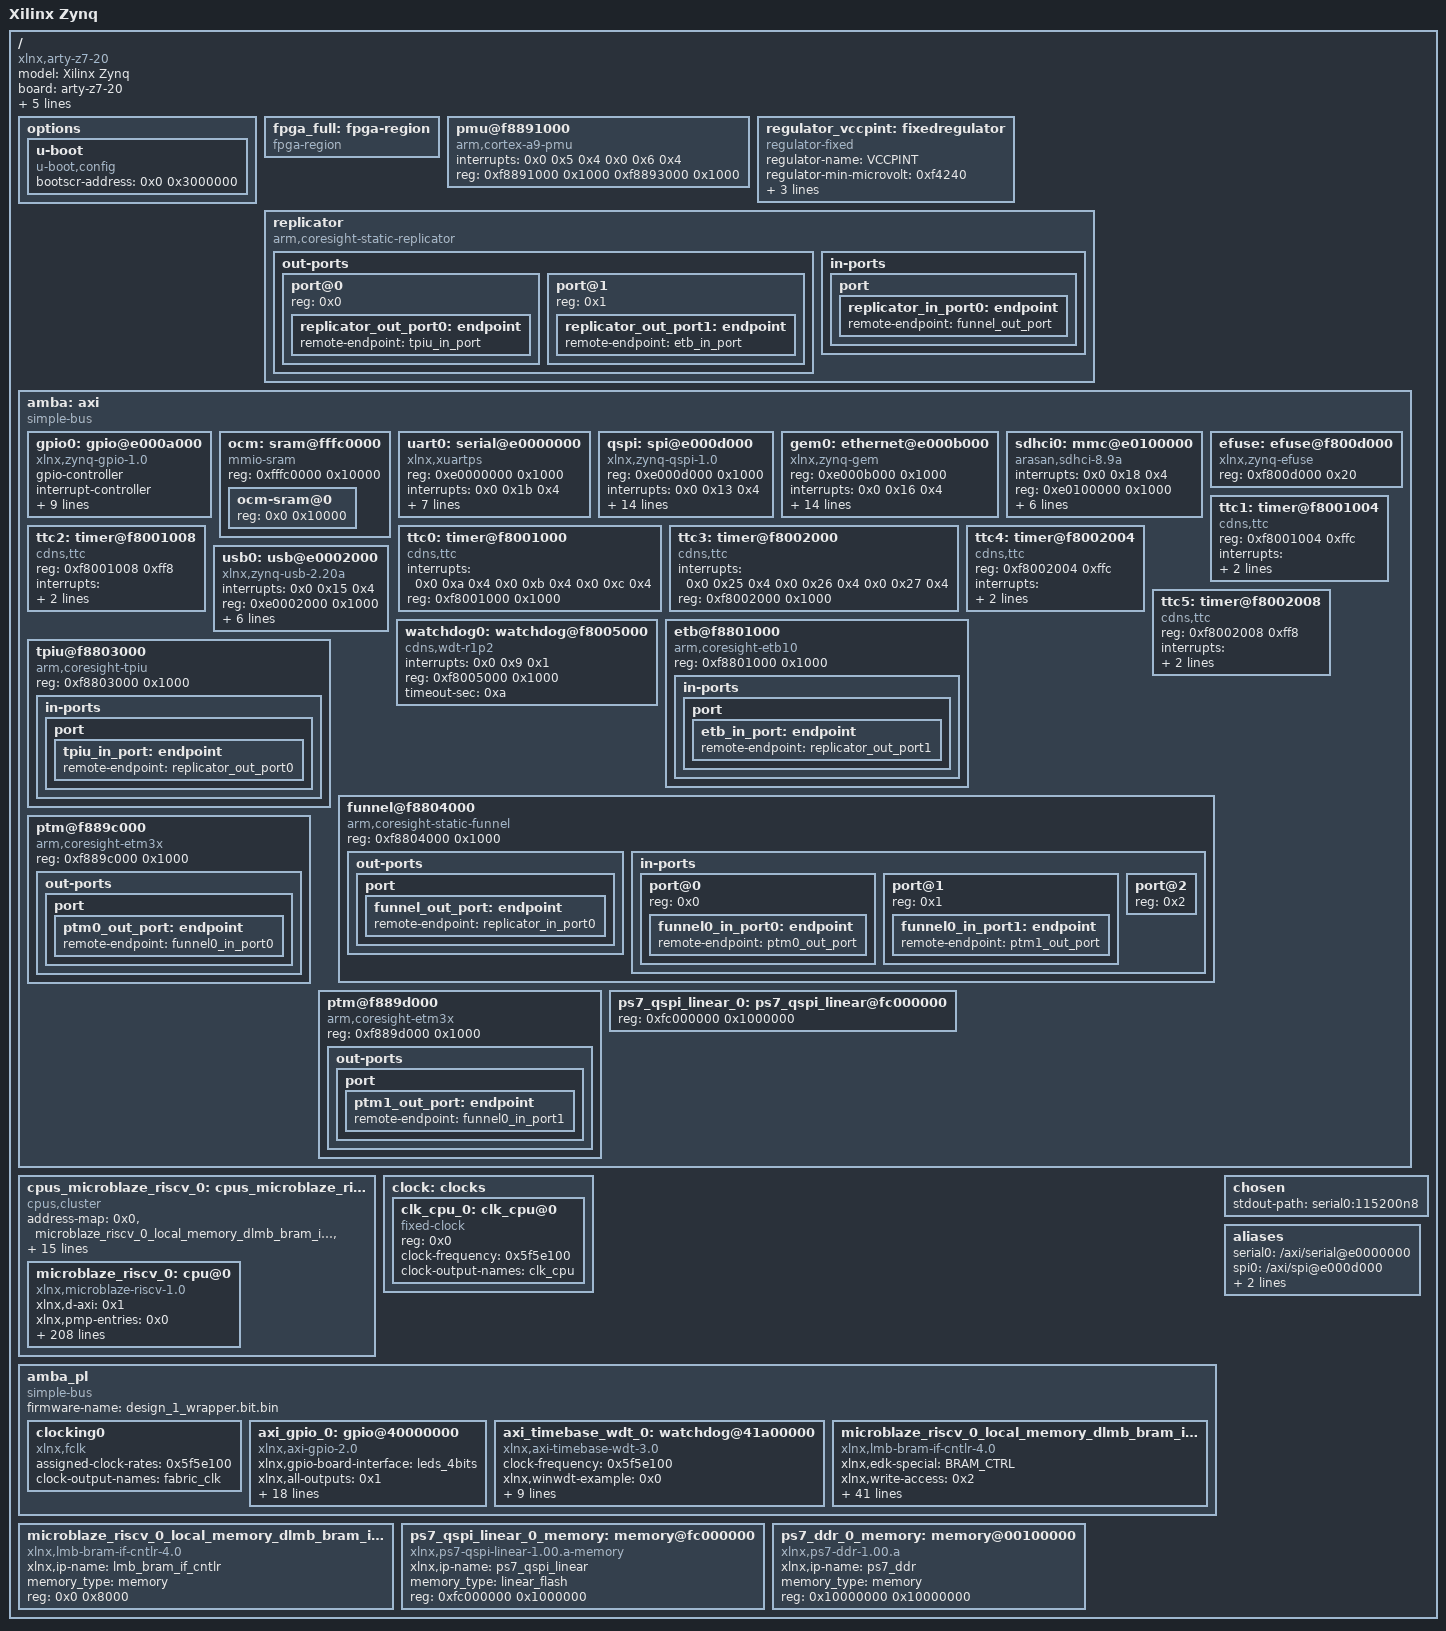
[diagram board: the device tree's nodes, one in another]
/dts-v1/;
/ {
        #address-cells = <0x1>;
        #size-cells = <0x1>;
        compatible = "xlnx,arty-z7-20";
        model = "Xilinx Zynq";
        board = "arty-z7-20";
        device_id = "7z020";
        slrcount = <0x1>;
        family = "Zynq";
        speed_grade = "1";
        pruned-sdt = <0x1>;

        options {

                u-boot {
                        compatible = "u-boot,config";
                        bootscr-address = <0x0 0x3000000>;
                };
        };

        fpga_full: fpga-region {
                phandle = <0x35>;
                compatible = "fpga-region";
                #address-cells = <0x1>;
                #size-cells = <0x1>;
                ranges;
        };

        pmu@f8891000 {
                compatible = "arm,cortex-a9-pmu";
                interrupts = <0x0 0x5 0x4 0x0 0x6 0x4>;
                reg = <0xf8891000 0x1000 0xf8893000 0x1000>;
        };

        regulator_vccpint: fixedregulator {
                phandle = <0x22>;
                compatible = "regulator-fixed";
                regulator-name = "VCCPINT";
                regulator-min-microvolt = <0xf4240>;
                regulator-max-microvolt = <0xf4240>;
                regulator-boot-on;
                regulator-always-on;
        };

        replicator {
                compatible = "arm,coresight-static-replicator";
                clock-names = "apb_pclk", "dbg_trc", "dbg_apb";

                out-ports {
                        #address-cells = <0x1>;
                        #size-cells = <0x0>;

                        port@0 {
                                reg = <0x0>;

                                replicator_out_port0: endpoint {
                                        phandle = <0x27>;
                                        remote-endpoint = <&tpiu_in_port>;
                                };
                        };

                        port@1 {
                                reg = <0x1>;

                                replicator_out_port1: endpoint {
                                        phandle = <0x26>;
                                        remote-endpoint = <&etb_in_port>;
                                };
                        };
                };

                in-ports {

                        port {

                                replicator_in_port0: endpoint {
                                        phandle = <0x28>;
                                        remote-endpoint = <&funnel_out_port>;
                                };
                        };
                };
        };

        amba: axi {
                phandle = <0x1>;
                bootph-all;
                compatible = "simple-bus";
                #address-cells = <0x1>;
                #size-cells = <0x1>;
                ranges;

                gpio0: gpio@e000a000 {
                        phandle = <0x7>;
                        compatible = "xlnx,zynq-gpio-1.0";
                        #gpio-cells = <0x2>;
                        gpio-controller;
                        interrupt-controller;
                        #interrupt-cells = <0x2>;
                        interrupts = <0x0 0x14 0x4>;
                        reg = <0xe000a000 0x1000>;
                        xlnx,mio-gpio-mask = <0x5600>;
                        status = "okay";
                        gpio-mask-high = <0x0>;
                        xlnx,emio-gpio-width = <0x40>;
                        xlnx,ip-name = "ps7_gpio";
                        gpio-mask-low = <0x5600>;
                        emio-gpio-width = <0x40>;
                        xlnx,name = "ps7_gpio_0";
                };

                ocm: sram@fffc0000 {
                        phandle = <0x3a>;
                        compatible = "mmio-sram";
                        reg = <0xfffc0000 0x10000>;
                        #address-cells = <0x1>;
                        #size-cells = <0x1>;
                        ranges = <0x0 0xfffc0000 0x10000>;

                        ocm-sram@0 {
                                reg = <0x0 0x10000>;
                        };
                };

                uart0: serial@e0000000 {
                        phandle = <0x5>;
                        compatible = "xlnx,xuartps", "cdns,uart-r1p8";
                        status = "okay";
                        clock-names = "uart_clk", "pclk";
                        reg = <0xe0000000 0x1000>;
                        interrupts = <0x0 0x1b 0x4>;
                        xlnx,clock-freq = <0x5f5e100>;
                        xlnx,has-modem = <0x0>;
                        xlnx,ip-name = "ps7_uart";
                        cts-override;
                        port-number = <0x0>;
                        xlnx,uart-clk-freq-hz = <0x5f5e100>;
                        xlnx,name = "ps7_uart_0";
                };

                qspi: spi@e000d000 {
                        phandle = <0xa>;
                        compatible = "xlnx,zynq-qspi-1.0";
                        reg = <0xe000d000 0x1000>;
                        interrupts = <0x0 0x13 0x4>;
                        clock-names = "ref_clk", "pclk";
                        status = "okay";
                        #address-cells = <0x1>;
                        #size-cells = <0x0>;
                        xlnx,qspi-fbclk = <0x0>;
                        num-cs = <0x1>;
                        xlnx,qspi-clk-freq-hz = <0xbebc200>;
                        xlnx,bus-width = <0x2>;
                        xlnx,ip-name = "ps7_qspi";
                        spi-rx-bus-width = <0x4>;
                        xlnx,connection-mode = <0x0>;
                        spi-tx-bus-width = <0x4>;
                        xlnx,clock-freq = <0xbebc200>;
                        xlnx,fb-clk = <0x1>;
                        xlnx,qspi-mode = <0x0>;
                        xlnx,name = "ps7_qspi_0";
                        xlnx,qspi-bus-width = <0x2>;
                        is-dual = <0x0>;
                };

                gem0: ethernet@e000b000 {
                        phandle = <0x8>;
                        compatible = "xlnx,zynq-gem", "cdns,gem";
                        reg = <0xe000b000 0x1000>;
                        status = "okay";
                        interrupts = <0x0 0x16 0x4>;
                        clock-names = "pclk", "hclk", "tx_clk";
                        #address-cells = <0x1>;
                        #size-cells = <0x0>;
                        xlnx,has-mdio = <0x1>;
                        phy-mode = "rgmii-id";
                        xlnx,enet-slcr-1000mbps-div0 = <0x8>;
                        xlnx,enet-slcr-10mbps-div0 = <0x8>;
                        enet-reset = <0x7 0x9 0x0>;
                        xlnx,enet-slcr-1000mbps-div1 = <0x1>;
                        xlnx,enet-slcr-10mbps-div1 = <0x32>;
                        xlnx,ip-name = "ps7_ethernet";
                        xlnx,eth-mode = <0x1>;
                        xlnx,enet-reset = "MIO , 9";
                        xlnx,enet-clk-freq-hz = <0x7735940>;
                        xlnx,enet-slcr-100mbps-div0 = <0x8>;
                        xlnx,enet-slcr-100mbps-div1 = <0x5>;
                        xlnx,name = "ps7_ethernet_0";
                };

                sdhci0: mmc@e0100000 {
                        phandle = <0x9>;
                        compatible = "arasan,sdhci-8.9a";
                        status = "okay";
                        clock-names = "clk_xin", "clk_ahb";
                        interrupts = <0x0 0x18 0x4>;
                        reg = <0xe0100000 0x1000>;
                        xlnx,has-power = <0x0>;
                        xlnx,ip-name = "ps7_sdio";
                        xlnx,sdio-clk-freq-hz = <0x2faf080>;
                        xlnx,has-wp = <0x0>;
                        xlnx,has-cd = <0x1>;
                        xlnx,name = "ps7_sd_0";
                };

                efuse: efuse@f800d000 {
                        phandle = <0x45>;
                        compatible = "xlnx,zynq-efuse";
                        reg = <0xf800d000 0x20>;
                };

                ttc0: timer@f8001000 {
                        phandle = <0x46>;
                        interrupts = <0x0 0xa 0x4 0x0 0xb 0x4 0x0 0xc 0x4>;
                        compatible = "cdns,ttc";
                        reg = <0xf8001000 0x1000>;
                };

                ttc1: timer@f8001004 {
                        phandle = <0x54>;
                        reg = <0xf8001004 0xffc>;
                        compatible = "cdns,ttc";
                        interrupts = <0x0 0xa 0x4 0x0 0xb 0x4 0x0 0xc 0x4>;
                        lop-dynamic-ttc-node = <0x1>;
                };

                ttc2: timer@f8001008 {
                        phandle = <0x55>;
                        reg = <0xf8001008 0xff8>;
                        compatible = "cdns,ttc";
                        interrupts = <0x0 0xa 0x4 0x0 0xb 0x4 0x0 0xc 0x4>;
                        lop-dynamic-ttc-node = <0x1>;
                };

                ttc3: timer@f8002000 {
                        phandle = <0x47>;
                        interrupts = <0x0 0x25 0x4 0x0 0x26 0x4 0x0 0x27 0x4>;
                        compatible = "cdns,ttc";
                        reg = <0xf8002000 0x1000>;
                };

                ttc4: timer@f8002004 {
                        phandle = <0x56>;
                        reg = <0xf8002004 0xffc>;
                        compatible = "cdns,ttc";
                        interrupts = <0x0 0x25 0x4 0x0 0x26 0x4 0x0 0x27 0x4>;
                        lop-dynamic-ttc-node = <0x1>;
                };

                ttc5: timer@f8002008 {
                        phandle = <0x57>;
                        reg = <0xf8002008 0xff8>;
                        compatible = "cdns,ttc";
                        interrupts = <0x0 0x25 0x4 0x0 0x26 0x4 0x0 0x27 0x4>;
                        lop-dynamic-ttc-node = <0x1>;
                };

                usb0: usb@e0002000 {
                        phandle = <0x6>;
                        compatible = "xlnx,zynq-usb-2.20a", "chipidea,usb2";
                        status = "okay";
                        interrupts = <0x0 0x15 0x4>;
                        reg = <0xe0002000 0x1000>;
                        phy_type = "ulpi";
                        xlnx,usb-reset = "MIO , 46";
                        xlnx,ip-name = "ps7_usb";
                        xlnx,enable-superspeed = <0x0>;
                        usb-reset = <0x7 0x2e 0x0>;
                        xlnx,name = "ps7_usb_0";
                };

                watchdog0: watchdog@f8005000 {
                        phandle = <0x49>;
                        compatible = "cdns,wdt-r1p2";
                        interrupts = <0x0 0x9 0x1>;
                        reg = <0xf8005000 0x1000>;
                        timeout-sec = <0xa>;
                };

                etb@f8801000 {
                        compatible = "arm,coresight-etb10", "arm,primecell";
                        reg = <0xf8801000 0x1000>;
                        clock-names = "apb_pclk", "dbg_trc", "dbg_apb";

                        in-ports {

                                port {

                                        etb_in_port: endpoint {
                                                phandle = <0x24>;
                                                remote-endpoint = <&replicator_out_port1>;
                                        };
                                };
                        };
                };

                tpiu@f8803000 {
                        compatible = "arm,coresight-tpiu", "arm,primecell";
                        reg = <0xf8803000 0x1000>;
                        clock-names = "apb_pclk", "dbg_trc", "dbg_apb";

                        in-ports {

                                port {

                                        tpiu_in_port: endpoint {
                                                phandle = <0x23>;
                                                remote-endpoint = <&replicator_out_port0>;
                                        };
                                };
                        };
                };

                funnel@f8804000 {
                        compatible = "arm,coresight-static-funnel", "arm,primecell";
                        reg = <0xf8804000 0x1000>;
                        clock-names = "apb_pclk", "dbg_trc", "dbg_apb";

                        out-ports {

                                port {

                                        funnel_out_port: endpoint {
                                                phandle = <0x25>;
                                                remote-endpoint = <&replicator_in_port0>;
                                        };
                                };
                        };

                        in-ports {
                                #address-cells = <0x1>;
                                #size-cells = <0x0>;

                                port@0 {
                                        reg = <0x0>;

                                        funnel0_in_port0: endpoint {
                                                phandle = <0x2c>;
                                                remote-endpoint = <&ptm0_out_port>;
                                        };
                                };

                                port@1 {
                                        reg = <0x1>;

                                        funnel0_in_port1: endpoint {
                                                phandle = <0x2e>;
                                                remote-endpoint = <&ptm1_out_port>;
                                        };
                                };

                                port@2 {
                                        reg = <0x2>;
                                };
                        };
                };

                ptm@f889c000 {
                        compatible = "arm,coresight-etm3x", "arm,primecell";
                        reg = <0xf889c000 0x1000>;
                        clock-names = "apb_pclk", "dbg_trc", "dbg_apb";

                        out-ports {

                                port {

                                        ptm0_out_port: endpoint {
                                                phandle = <0x29>;
                                                remote-endpoint = <&funnel0_in_port0>;
                                        };
                                };
                        };
                };

                ptm@f889d000 {
                        compatible = "arm,coresight-etm3x", "arm,primecell";
                        reg = <0xf889d000 0x1000>;
                        clock-names = "apb_pclk", "dbg_trc", "dbg_apb";

                        out-ports {

                                port {

                                        ptm1_out_port: endpoint {
                                                phandle = <0x2a>;
                                                remote-endpoint = <&funnel0_in_port1>;
                                        };
                                };
                        };
                };

                ps7_qspi_linear_0: ps7_qspi_linear@fc000000 {
                        phandle = <0x4e>;
                        reg = <0xfc000000 0x1000000>;
                };
        };

        cpus_microblaze_riscv_0: cpus_microblaze_riscv@0 {
                phandle = <0x4f>;
                #cpu-mask-cells = <0x1>;
                compatible = "cpus,cluster";
                #address-cells = <0x1>;
                #size-cells = <0x0>;
                address-map = <0x0 &microblaze_riscv_0_local_memory_dlmb_bram_if_cntlr_memory 0x0 0x8000>,
                 <0x0 &microblaze_riscv_0_local_memory_dlmb_bram_if_cntlr 0x0 0x8000>,
                 <0x10000000 &ps7_ddr_0_memory 0x10000000 0x10000000>,
                 <0x40000000 &axi_gpio_0 0x40000000 0x10000>,
                 <0x41a00000 &axi_timebase_wdt_0 0x41a00000 0x10000>,
                 <0xe0000000 &uart0 0xe0000000 0x1000>,
                 <0xe0002000 &usb0 0xe0002000 0x1000>,
                 <0xe000a000 &gpio0 0xe000a000 0x1000>,
                 <0xe000b000 &gem0 0xe000b000 0x1000>,
                 <0xe0100000 &sdhci0 0xe0100000 0x1000>,
                 <0xe000d000 &qspi 0xe000d000 0x1000>,
                 <0xfc000000 &ps7_qspi_linear_0_memory 0xfc000000 0x1000000>;
                #ranges-address-cells = <0x1>;
                #ranges-size-cells = <0x1>;

                microblaze_riscv_0: cpu@0 {
                        phandle = <0x50>;
                        xlnx,d-axi = <0x1>;
                        xlnx,pmp-entries = <0x0>;
                        xlnx,temporal-depth = <0x0>;
                        xlnx,dcache-force-tag-lutram = <0x0>;
                        reg = <0x0>;
                        xlnx,interrupt-is-edge = <0x0>;
                        xlnx,use-mmu = <0x0>;
                        xlnx,dc-axi-mon = <0x0>;
                        xlnx,debug-trace-async-reset = <0x0>;
                        xlnx,part = "xc7z020clg400-1";
                        xlnx,use-config-reset = <0x0>;
                        xlnx,family = "zynq";
                        xlnx,use-sleep = <0x0>;
                        xlnx,enable-discrete-ports = <0x0>;
                        xlnx,d-lmb = <0x1>;
                        xlnx,debug-interface = <0x0>;
                        xlnx,use-ext-brk = <0x0>;
                        xlnx,debug-enabled = <0x1>;
                        xlnx,daddr-size = <0x20>;
                        xlnx,use-extended-fsl-instr = <0x0>;
                        xlnx,branch-target-cache-size = <0x0>;
                        bus-handle = <0x33>;
                        xlnx,pmp-addr0 = <0x0>;
                        xlnx,pmp-addr1 = <0x0>;
                        xlnx,pmp-addr2 = <0x0>;
                        xlnx,pmp-addr3 = <0x0>;
                        xlnx,pmp-addr4 = <0x0>;
                        xlnx,edk-special = "microblaze_riscv";
                        xlnx,use-dcache = <0x0>;
                        xlnx,pmp-addr5 = <0x0>;
                        xlnx,use-muldiv = <0x0>;
                        xlnx,pmp-addr6 = <0x0>;
                        xlnx,use-axi-dp-ext-addr = <0x0>;
                        xlnx,pmp-addr7 = <0x0>;
                        xlnx,pmp-addr8 = <0x0>;
                        xlnx,pmp-addr9 = <0x0>;
                        xlnx,i-axi = <0x0>;
                        xlnx,icache-streams = <0x0>;
                        xlnx,i-lmb-has-prot = <0x0>;
                        xlnx,num-sync-ff-dbg-clk = <0x1>;
                        xlnx,icache-byte-size = <0x2000>;
                        xlnx,pmp-addr10 = <0x0>;
                        d-cache-size = <0x2000>;
                        xlnx,pmp-addr11 = <0x0>;
                        xlnx,pmp-addr12 = <0x0>;
                        xlnx,pmp-addr13 = <0x0>;
                        xlnx,pmp-addr14 = <0x0>;
                        xlnx,pmp-addr15 = <0x0>;
                        xlnx,avoid-primitives = <0x0>;
                        xlnx,pmp-addr16 = <0x0>;
                        xlnx,pmp-addr17 = <0x0>;
                        xlnx,pmp-addr18 = <0x0>;
                        xlnx,pdaddr-size = <0x20>;
                        xlnx,pmp-addr19 = <0x0>;
                        xlnx,pmp-addr20 = <0x0>;
                        xlnx,pmp-addr21 = <0x0>;
                        xlnx,i-lmb = <0x1>;
                        xlnx,pmp-addr22 = <0x0>;
                        xlnx,lmb-data-size = <0x20>;
                        xlnx,lockstep-select = <0x0>;
                        xlnx,pmp-addr23 = <0x0>;
                        timebase-frequency = <0x5f5e100>;
                        xlnx,pmp-addr24 = <0x0>;
                        xlnx,dcache-data-width = <0x0>;
                        xlnx,icache-force-tag-lutram = <0x0>;
                        xlnx,pmp-addr25 = <0x0>;
                        xlnx,pmp-addr26 = <0x0>;
                        xlnx,use-branch-target-cache = <0x0>;
                        xlnx,pmp-addr27 = <0x0>;
                        xlnx,number-of-pc-brk = <0x1>;
                        xlnx,pmp-addr28 = <0x0>;
                        xlnx,imprecise-exceptions = <0x0>;
                        xlnx,pmp-addr29 = <0x0>;
                        xlnx,pmp-addr30 = <0x0>;
                        xlnx,pmp-addr31 = <0x0>;
                        xlnx,pmp-addr32 = <0x0>;
                        model = "microblaze_riscv,1.0";
                        xlnx,pmp-addr33 = <0x0>;
                        xlnx,pmp-addr34 = <0x0>;
                        xlnx,pmp-addr35 = <0x0>;
                        xlnx,pmp-addr36 = <0x0>;
                        d-cache-highaddr = <0x3fffffff>;
                        xlnx,optimization = <0x0>;
                        xlnx,pmp-addr37 = <0x0>;
                        xlnx,pmp-addr38 = <0x0>;
                        xlnx,pmp-addr39 = <0x0>;
                        xlnx,pmp-addr40 = <0x0>;
                        xlnx,pmp-addr41 = <0x0>;
                        xlnx,d-lmb-mon = <0x0>;
                        xlnx,pmp-addr42 = <0x0>;
                        xlnx,pmp-addr43 = <0x0>;
                        xlnx,pmp-addr44 = <0x0>;
                        xlnx,pmp-addr45 = <0x0>;
                        xlnx,pmp-addr46 = <0x0>;
                        xlnx,pmp-addr47 = <0x0>;
                        xlnx,pmp-addr48 = <0x0>;
                        xlnx,fault-tolerant = <0x0>;
                        xlnx,pmp-addr49 = <0x0>;
                        xlnx,pmp-addr50 = <0x0>;
                        xlnx,pmp-addr51 = <0x0>;
                        xlnx,pmp-enhancements = <0x0>;
                        d-cache-line-size = <0x10>;
                        xlnx,mmu-privileged-instr = <0x0>;
                        xlnx,pmp-addr52 = <0x0>;
                        clock-frequency = <0x5f5e100>;
                        xlnx,pmp-addr53 = <0x0>;
                        xlnx,pmp-addr54 = <0x0>;
                        xlnx,pmp-addr55 = <0x0>;
                        xlnx,i-lmb-protocol = <0x0>;
                        xlnx,pmp-addr56 = <0x0>;
                        xlnx,pmp-addr57 = <0x0>;
                        xlnx,dp-axi-mon = <0x0>;
                        xlnx,pmp-addr58 = <0x0>;
                        xlnx,pmp-addr59 = <0x0>;
                        xlnx,pmp-addr60 = <0x0>;
                        xlnx,pmp-addr61 = <0x0>;
                        xlnx,pmp-addr62 = <0x0>;
                        xlnx,pmp-addr63 = <0x0>;
                        xlnx,debug-external-trace = <0x0>;
                        xlnx,addr-size = <0x20>;
                        xlnx,debug-num-progbuf = <0x2>;
                        xlnx,debug-event-counters = <0x0>;
                        xlnx,edk-iptype = "PROCESSOR";
                        xlnx,debug-latency-counters = <0x0>;
                        xlnx,interconnect = <0x2>;
                        xlnx,edge-is-positive = <0x1>;
                        xlnx,use-icache = <0x0>;
                        xlnx,async-wakeup = <0x3>;
                        xlnx,s-axi = <0x0>;
                        xlnx,use-ext-nm-brk = <0x0>;
                        xlnx,ic-axi-mon = <0x0>;
                        xlnx,archid = <0x1>;
                        xlnx,num-sync-ff-clk-irq = <0x1>;
                        xlnx,freq = <0x5f5e100>;
                        xlnx,lockstep-master = <0x0>;
                        xlnx,pmp-cfg0 = <0x0>;
                        xlnx,pmp-cfg1 = <0x0>;
                        xlnx,iaddr-size = <0x20>;
                        xlnx,interrupt-mon = <0x0>;
                        xlnx,pmp-cfg2 = <0x0>;
                        xlnx,number-of-wr-addr-brk = <0x0>;
                        xlnx,pmp-cfg3 = <0x0>;
                        xlnx,pmp-cfg4 = <0x0>;
                        xlnx,use-interrupt = <0x0>;
                        xlnx,pmp-cfg5 = <0x0>;
                        xlnx,async-interrupt = <0x1>;
                        xlnx,pc-width = <0xf>;
                        xlnx,pmp-cfg6 = <0x0>;
                        xlnx,icache-victims = <0x0>;
                        xlnx,pmp-cfg7 = <0x0>;
                        xlnx,pmp-cfg8 = <0x0>;
                        xlnx,pmp-cfg9 = <0x0>;
                        xlnx,use-bitman-a = <0x0>;
                        xlnx,use-bitman-b = <0x0>;
                        xlnx,use-bitman-c = <0x0>;
                        xlnx,i-lmb-mon = <0x0>;
                        xlnx,dcache-byte-size = <0x2000>;
                        xlnx,data-size = <0x20>;
                        compatible = "xlnx,microblaze-riscv-1.0", "xlnx,microblaze_riscv";
                        xlnx,pmp-debug-inhibit = <0x0>;
                        xlnx,use-sstc = <0x1>;
                        xlnx,fsl-exception = <0x0>;
                        xlnx,dcache-use-writeback = <0x0>;
                        device_type = "cpu";
                        xlnx,impid = <0x1>;
                        xlnx,use-bitman-s = <0x0>;
                        xlnx,base-vectors = <0x0>;
                        xlnx,icache-line-len = <0x4>;
                        xlnx,d-lmb-has-prot = <0x0>;
                        xlnx,use-barrel = <0x1>;
                        xlnx,misaligned-exceptions = <0x1>;
                        xlnx,piaddr-size = <0x20>;
                        xlnx,use-bitman = <0x0>;
                        xlnx,dcache-line-len = <0x4>;
                        xlnx,num-sync-ff-clk = <0x2>;
                        xlnx,memory-ip-list = "microblaze_riscv_0_local_memory_ilmb_bram_if_cntlr_memory", "microblaze_riscv_0_local_memory_dlmb_bram_if_cntlr_memory";
                        xlnx,number-of-rd-addr-brk = <0x0>;
                        xlnx,use-counters = <0x1>;
                        xlnx,lockstep-slave = <0x0>;
                        xlnx,pmp-cfg10 = <0x0>;
                        xlnx,pmp-cfg11 = <0x0>;
                        xlnx,debug-profile-size = <0x0>;
                        xlnx,pmp-cfg12 = <0x0>;
                        xlnx,pmp-cfg13 = <0x0>;
                        xlnx,pmp-cfg14 = <0x0>;
                        xlnx,pmp-cfg15 = <0x0>;
                        xlnx,debug-counter-width = <0x40>;
                        xlnx,icache-data-width = <0x0>;
                        xlnx,ip-name = "microblaze_riscv";
                        xlnx,ip-axi-mon = <0x0>;
                        xlnx,d-lmb-protocol = <0x0>;
                        xlnx,trace = <0x0>;
                        xlnx,ill-instr-exception = <0x2>;
                        xlnx,debug-trace-size = <0x0>;
                        xlnx,pmp-granularity = <0x2>;
                        xlnx,num-sync-ff-dbg-trace-clk = <0x2>;
                        xlnx,ecc-use-ce-exception = <0x0>;
                        xlnx,num-sync-ff-clk-debug = <0x2>;
                        xlnx,use-atomic = <0x0>;
                        xlnx,g-template-list = <0x0>;
                        xlnx,trap-enhancement = <0x0>;
                        xlnx,hartid = <0x0>;
                        xlnx,use-fpu = <0x0>;
                        xlnx,use-non-secure = <0x0>;
                        d-cache-baseaddr = <0x0>;
                        xlnx,use-compression = <0x0>;
                        xlnx,instr-size = <0x20>;
                        xlnx,fsl-links = <0x0>;
                        xlnx,dcache-victims = <0x0>;
                        xlnx,pmp-read-only = <0x0>;
                };
        };

        clock: clocks {
                phandle = <0x51>;
                #address-cells = <0x1>;
                #size-cells = <0x0>;

                clk_cpu_0: clk_cpu@0 {
                        phandle = <0x52>;
                        compatible = "fixed-clock";
                        reg = <0x0>;
                        clock-frequency = <0x5f5e100>;
                        clock-output-names = "clk_cpu";
                        #clock-cells = <0x0>;
                };
        };

        amba_pl: amba_pl {
                phandle = <0x33>;
                ranges;
                compatible = "simple-bus";
                #address-cells = <0x1>;
                #size-cells = <0x1>;
                firmware-name = "design_1_wrapper.bit.bin";

                clocking0: clocking0 {
                        phandle = <0x53>;
                        compatible = "xlnx,fclk";
                        assigned-clock-rates = <0x5f5e100>;
                        #clock-cells = <0x0>;
                        clock-output-names = "fabric_clk";
                };

                axi_gpio_0: gpio@40000000 {
                        phandle = <0x31>;
                        xlnx,gpio-board-interface = "leds_4bits";
                        compatible = "xlnx,axi-gpio-2.0", "xlnx,xps-gpio-1.00.a";
                        xlnx,all-outputs = <0x1>;
                        #gpio-cells = <0x2>;
                        xlnx,gpio-width = <0x4>;
                        xlnx,dout-default = <0x0>;
                        xlnx,is-dual = <0x0>;
                        xlnx,ip-name = "axi_gpio";
                        xlnx,tri-default-2 = <0xffffffff>;
                        reg = <0x40000000 0x10000>;
                        xlnx,all-inputs-2 = <0x0>;
                        xlnx,all-outputs-2 = <0x0>;
                        gpio-controller;
                        xlnx,interrupt-present = <0x0>;
                        xlnx,gpio2-board-interface = "Custom";
                        xlnx,edk-iptype = "PERIPHERAL";
                        xlnx,dout-default-2 = <0x0>;
                        status = "okay";
                        xlnx,gpio2-width = <0x20>;
                        clock-names = "s_axi_aclk";
                        xlnx,use-board-flow;
                        xlnx,tri-default = <0xffffffff>;
                        xlnx,name = "axi_gpio_0";
                        xlnx,all-inputs = <0x0>;
                };

                axi_timebase_wdt_0: watchdog@41a00000 {
                        phandle = <0x32>;
                        compatible = "xlnx,axi-timebase-wdt-3.0", "xlnx,xps-timebase-wdt-1.00.a";
                        clock-frequency = <0x5f5e100>;
                        xlnx,winwdt-example = <0x0>;
                        xlnx,ip-name = "axi_timebase_wdt";
                        reg = <0x41a00000 0x10000>;
                        xlnx,max-count-width = <0x20>;
                        xlnx,edk-iptype = "PERIPHERAL";
                        xlnx,sst-count-width = <0x8>;
                        xlnx,wdt-enable-once = <0x1>;
                        status = "okay";
                        clock-names = "s_axi_aclk";
                        xlnx,enable-window-wdt = <0x0>;
                        xlnx,name = "axi_timebase_wdt_0";
                        xlnx,wdt-interval = <0x1e>;
                };

                microblaze_riscv_0_local_memory_dlmb_bram_if_cntlr: lmb_bram_if_cntlr@0 {
                        phandle = <0x30>;
                        xlnx,edk-special = "BRAM_CTRL";
                        xlnx,write-access = <0x2>;
                        compatible = "xlnx,lmb-bram-if-cntlr-4.0", "xlnx,axi-bram-ctrl";
                        xlnx,ecc-onoff-register = <0x0>;
                        xlnx,ecc-onoff-reset-value = <0x1>;
                        xlnx,s-axi-ctrl-protocol = "AXI4LITE";
                        xlnx,mask = <0x50000000>;
                        xlnx,mask1 = <0x800000>;
                        xlnx,mask2 = <0x800000>;
                        xlnx,fault-inject = <0x0>;
                        xlnx,mask3 = <0x800000>;
                        xlnx,ip-name = "lmb_bram_if_cntlr";
                        xlnx,arbitration = <0x0>;
                        xlnx,num-lmb = <0x1>;
                        xlnx,mask4 = <0x800000>;
                        reg = <0x0 0x8000>;
                        xlnx,s-axi-ctrl-addr-width = <0x20>;
                        xlnx,mask5 = <0x800000>;
                        xlnx,ecc-status-registers = <0x0>;
                        xlnx,prot-cfg = <0xff>;
                        xlnx,mask6 = <0x800000>;
                        xlnx,lmb-protocol = <0x0>;
                        xlnx,ce-counter-width = <0x0>;
                        xlnx,prot-cfg1 = <0xff>;
                        xlnx,mask7 = <0x800000>;
                        xlnx,ecc = <0x0>;
                        xlnx,edk-iptype = "PERIPHERAL";
                        xlnx,prot-cfg2 = <0xff>;
                        xlnx,lmb-dwidth = <0x20>;
                        xlnx,interconnect = <0x0>;
                        xlnx,ce-failing-registers = <0x0>;
                        xlnx,prot-cfg3 = <0xff>;
                        xlnx,ue-failing-registers = <0x0>;
                        xlnx,prot-cfg4 = <0xff>;
                        xlnx,lmb-has-prot = <0x0>;
                        status = "okay";
                        xlnx,data-width = <0x20>;
                        xlnx,prot-cfg5 = <0xff>;
                        xlnx,s-axi-ctrl-data-width = <0x20>;
                        xlnx,prot-cfg6 = <0xff>;
                        xlnx,bram-awidth = <0x20>;
                        xlnx,prot-cfg7 = <0xff>;
                        xlnx,lmb-awidth = <0x20>;
                        xlnx,name = "microblaze_riscv_0_local_memory_dlmb_bram_if_cntlr";
                };
        };

        microblaze_riscv_0_local_memory_dlmb_bram_if_cntlr_memory: memory@0 {
                phandle = <0x2f>;
                compatible = "xlnx,lmb-bram-if-cntlr-4.0";
                xlnx,ip-name = "lmb_bram_if_cntlr";
                device_type = "memory";
                memory_type = "memory";
                reg = <0x0 0x8000>;
        };

        ps7_qspi_linear_0_memory: memory@fc000000 {
                phandle = <0xb>;
                compatible = "xlnx,ps7-qspi-linear-1.00.a-memory";
                xlnx,ip-name = "ps7_qspi_linear";
                device_type = "memory";
                memory_type = "linear_flash";
                reg = <0xfc000000 0x1000000>;
        };

        ps7_ddr_0_memory: memory@00100000 {
                phandle = <0x2>;
                compatible = "xlnx,ps7-ddr-1.00.a";
                xlnx,ip-name = "ps7_ddr";
                device_type = "memory";
                memory_type = "memory";
                reg = <0x10000000 0x10000000>;
        };

        chosen {
                stdout-path = "serial0:115200n8";
        };

        aliases {
                serial0 = "/axi/serial@e0000000";
                spi0 = "/axi/spi@e000d000";
                serial1 = "/axi/coresight@f8800000";
                ethernet0 = "/axi/ethernet@e000b000";
        };

        __symbols__ {
                fpga_full = "/fpga-region";
                regulator_vccpint = "/fixedregulator";
                replicator_out_port0 = "/replicator/out-ports/port@0/endpoint";
                replicator_out_port1 = "/replicator/out-ports/port@1/endpoint";
                replicator_in_port0 = "/replicator/in-ports/port/endpoint";
                amba = "/axi";
                gpio0 = "/axi/gpio@e000a000";
                ocm = "/axi/sram@fffc0000";
                uart0 = "/axi/serial@e0000000";
                qspi = "/axi/spi@e000d000";
                gem0 = "/axi/ethernet@e000b000";
                sdhci0 = "/axi/mmc@e0100000";
                efuse = "/axi/efuse@f800d000";
                usb0 = "/axi/usb@e0002000";
                watchdog0 = "/axi/watchdog@f8005000";
                etb_in_port = "/axi/etb@f8801000/in-ports/port/endpoint";
                tpiu_in_port = "/axi/tpiu@f8803000/in-ports/port/endpoint";
                funnel_out_port = "/axi/funnel@f8804000/out-ports/port/endpoint";
                funnel0_in_port0 = "/axi/funnel@f8804000/in-ports/port@0/endpoint";
                funnel0_in_port1 = "/axi/funnel@f8804000/in-ports/port@1/endpoint";
                ptm0_out_port = "/axi/ptm@f889c000/out-ports/port/endpoint";
                ptm1_out_port = "/axi/ptm@f889d000/out-ports/port/endpoint";
                ps7_qspi_linear_0 = "/axi/ps7_qspi_linear@fc000000";
                cpus_microblaze_riscv_0 = "/cpus_microblaze_riscv@0";
                microblaze_riscv_0 = "/cpus_microblaze_riscv@0/cpu@0";
                clock = "/clocks";
                clk_cpu_0 = "/clocks/clk_cpu@0";
                amba_pl = "/amba_pl";
                clocking0 = "/amba_pl/clocking0";
                axi_gpio_0 = "/amba_pl/gpio@40000000";
                axi_timebase_wdt_0 = "/amba_pl/watchdog@41a00000";
                microblaze_riscv_0_local_memory_dlmb_bram_if_cntlr = "/amba_pl/lmb_bram_if_cntlr@0";
                microblaze_riscv_0_local_memory_dlmb_bram_if_cntlr_memory = "/memory@0";
                ps7_qspi_linear_0_memory = "/memory@fc000000";
                ps7_ddr_0_memory = "/memory@00100000";
        };
};
